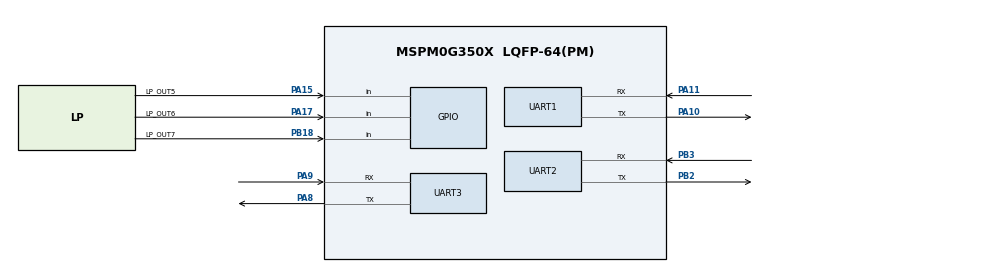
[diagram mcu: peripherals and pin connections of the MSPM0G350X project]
/**
 * @cliArgs --device "MSPM0G350X" --part "Default" --package "LQFP-64(PM)" --product "mspm0_sdk@2.09.00.00"
 * @versions {"tool":"1.27.0+4565"}
 */

/**
 * Import the modules used in this configuration.
 */
const GPIO    = scripting.addModule("/ti/driverlib/GPIO", {}, false);
const GPIO1   = GPIO.addInstance();
const SYSCTL  = scripting.addModule("/ti/driverlib/SYSCTL");
const SYSTICK = scripting.addModule("/ti/driverlib/SYSTICK");
const TIMER   = scripting.addModule("/ti/driverlib/TIMER", {}, false);
const TIMER1  = TIMER.addInstance();
const UART    = scripting.addModule("/ti/driverlib/UART", {}, false);
const UART1   = UART.addInstance();
const UART2   = UART.addInstance();
const UART3   = UART.addInstance();

/**
 * Write custom configuration values to the imported modules.
 */
const divider6       = system.clockTree["PLL_CLK2X_DIV"];
divider6.divideValue = 4;

const divider7       = system.clockTree["PLL_PDIV"];
divider7.divideValue = 2;

const divider9       = system.clockTree["UDIV"];
divider9.divideValue = 2;

const gate7  = system.clockTree["MFCLKGATE"];
gate7.enable = true;

const multiplier2         = system.clockTree["PLL_QDIV"];
multiplier2.multiplyValue = 10;

const mux8       = system.clockTree["HSCLKMUX"];
mux8.inputSelect = "HSCLKMUX_SYSPLL2X";

GPIO1.$name                              = "GPIO_LinePatrol";
GPIO1.associatedPins.create(8);
GPIO1.associatedPins[0].assignedPort     = "PORTA";
GPIO1.associatedPins[0].assignedPin      = "26";
GPIO1.associatedPins[0].$name            = "LP_OUT1";
GPIO1.associatedPins[0].direction        = "INPUT";
GPIO1.associatedPins[0].internalResistor = "PULL_DOWN";
GPIO1.associatedPins[1].assignedPort     = "PORTA";
GPIO1.associatedPins[1].assignedPin      = "24";
GPIO1.associatedPins[1].$name            = "LP_OUT2";
GPIO1.associatedPins[1].direction        = "INPUT";
GPIO1.associatedPins[1].internalResistor = "PULL_DOWN";
GPIO1.associatedPins[2].$name            = "LP_OUT3";
GPIO1.associatedPins[2].direction        = "INPUT";
GPIO1.associatedPins[2].internalResistor = "PULL_DOWN";
GPIO1.associatedPins[2].assignedPort     = "PORTB";
GPIO1.associatedPins[2].assignedPin      = "24";
GPIO1.associatedPins[3].assignedPort     = "PORTA";
GPIO1.associatedPins[3].$name            = "LP_OUT4";
GPIO1.associatedPins[3].direction        = "INPUT";
GPIO1.associatedPins[3].internalResistor = "PULL_DOWN";
GPIO1.associatedPins[3].assignedPin      = "22";
GPIO1.associatedPins[4].assignedPort     = "PORTA";
GPIO1.associatedPins[4].$name            = "LP_OUT5";
GPIO1.associatedPins[4].direction        = "INPUT";
GPIO1.associatedPins[4].internalResistor = "PULL_DOWN";
GPIO1.associatedPins[4].assignedPin      = "15";
GPIO1.associatedPins[4].pin.$assign      = "PA15";
GPIO1.associatedPins[5].assignedPort     = "PORTA";
GPIO1.associatedPins[5].$name            = "LP_OUT6";
GPIO1.associatedPins[5].direction        = "INPUT";
GPIO1.associatedPins[5].internalResistor = "PULL_DOWN";
GPIO1.associatedPins[5].assignedPin      = "17";
GPIO1.associatedPins[5].pin.$assign      = "PA17";
GPIO1.associatedPins[6].$name            = "LP_OUT7";
GPIO1.associatedPins[6].direction        = "INPUT";
GPIO1.associatedPins[6].internalResistor = "PULL_DOWN";
GPIO1.associatedPins[6].assignedPort     = "PORTB";
GPIO1.associatedPins[6].assignedPin      = "18";
GPIO1.associatedPins[6].pin.$assign      = "PB18";
GPIO1.associatedPins[7].$name            = "LP_OUT8";
GPIO1.associatedPins[7].direction        = "INPUT";
GPIO1.associatedPins[7].internalResistor = "PULL_DOWN";
GPIO1.associatedPins[7].assignedPort     = "PORTA";
GPIO1.associatedPins[7].assignedPin      = "21";

const Board = scripting.addModule("/ti/driverlib/Board", {}, false);

SYSCTL.forceDefaultClkConfig = true;
SYSCTL.clockTreeEn           = true;

SYSTICK.periodEnable      = true;
SYSTICK.period            = 80000;
SYSTICK.interruptPriority = "1";
SYSTICK.interruptEnable   = true;
SYSTICK.systickEnable     = true;

TIMER1.$name             = "TIMER_1MS";
TIMER1.timerStartTimer   = true;
TIMER1.timerMode         = "PERIODIC_UP";
TIMER1.timerPeriod       = "1 ms";
TIMER1.timerClkDiv       = 8;
TIMER1.timerClkPrescale  = 100;
TIMER1.interruptPriority = "2";
TIMER1.interrupts        = ["ZERO"];

UART1.$name                            = "user";
UART1.uartClkSrc                       = "MFCLK";
UART1.targetBaudRate                   = 115200;
UART1.peripheral.rxPin.$assign         = "PA11";
UART1.peripheral.txPin.$assign         = "PA10";
UART1.txPinConfig.$name                = "ti_driverlib_gpio_GPIOPinGeneric0";
UART1.txPinConfig.direction            = scripting.forceWrite("OUTPUT");
UART1.txPinConfig.hideOutputInversion  = scripting.forceWrite(false);
UART1.txPinConfig.onlyInternalResistor = scripting.forceWrite(false);
UART1.txPinConfig.passedPeripheralType = scripting.forceWrite("Digital");
UART1.rxPinConfig.$name                = "ti_driverlib_gpio_GPIOPinGeneric1";
UART1.rxPinConfig.hideOutputInversion  = scripting.forceWrite(false);
UART1.rxPinConfig.onlyInternalResistor = scripting.forceWrite(false);
UART1.rxPinConfig.passedPeripheralType = scripting.forceWrite("Digital");

UART2.$name                            = "MSPMotor";
UART2.targetBaudRate                   = 115200;
UART2.uartClkSrc                       = "MFCLK";
UART2.enabledInterrupts                = ["RX"];
UART2.interruptPriority                = "0";
UART2.peripheral.$assign               = "UART3";
UART2.peripheral.rxPin.$assign         = "PB3";
UART2.peripheral.txPin.$assign         = "PB2";
UART2.txPinConfig.$name                = "ti_driverlib_gpio_GPIOPinGeneric2";
UART2.txPinConfig.direction            = scripting.forceWrite("OUTPUT");
UART2.txPinConfig.hideOutputInversion  = scripting.forceWrite(false);
UART2.txPinConfig.onlyInternalResistor = scripting.forceWrite(false);
UART2.txPinConfig.passedPeripheralType = scripting.forceWrite("Digital");
UART2.rxPinConfig.$name                = "ti_driverlib_gpio_GPIOPinGeneric3";
UART2.rxPinConfig.hideOutputInversion  = scripting.forceWrite(false);
UART2.rxPinConfig.onlyInternalResistor = scripting.forceWrite(false);
UART2.rxPinConfig.passedPeripheralType = scripting.forceWrite("Digital");

UART3.$name                            = "Motor";
UART3.targetBaudRate                   = 115200;
UART3.uartClkSrc                       = "MFCLK";
UART3.peripheral.$assign               = "UART1";
UART3.peripheral.rxPin.$assign         = "PA9";
UART3.peripheral.txPin.$assign         = "PA8";
UART3.txPinConfig.$name                = "ti_driverlib_gpio_GPIOPinGeneric4";
UART3.txPinConfig.direction            = scripting.forceWrite("OUTPUT");
UART3.txPinConfig.hideOutputInversion  = scripting.forceWrite(false);
UART3.txPinConfig.onlyInternalResistor = scripting.forceWrite(false);
UART3.txPinConfig.passedPeripheralType = scripting.forceWrite("Digital");
UART3.rxPinConfig.$name                = "ti_driverlib_gpio_GPIOPinGeneric5";
UART3.rxPinConfig.hideOutputInversion  = scripting.forceWrite(false);
UART3.rxPinConfig.onlyInternalResistor = scripting.forceWrite(false);
UART3.rxPinConfig.passedPeripheralType = scripting.forceWrite("Digital");

/**
 * Pinmux solution for unlocked pins/peripherals. This ensures that minor changes to the automatic solver in a future
 * version of the tool will not impact the pinmux you originally saw.  These lines can be completely deleted in order to
 * re-solve from scratch.
 */
GPIO1.associatedPins[0].pin.$suggestSolution = "PA26";
GPIO1.associatedPins[1].pin.$suggestSolution = "PA24";
GPIO1.associatedPins[2].pin.$suggestSolution = "PB24";
GPIO1.associatedPins[3].pin.$suggestSolution = "PA22";
GPIO1.associatedPins[7].pin.$suggestSolution = "PA21";
Board.peripheral.$suggestSolution            = "DEBUGSS";
Board.peripheral.swclkPin.$suggestSolution   = "PA20";
Board.peripheral.swdioPin.$suggestSolution   = "PA19";
TIMER1.peripheral.$suggestSolution           = "TIMA0";
UART1.peripheral.$suggestSolution            = "UART0";
